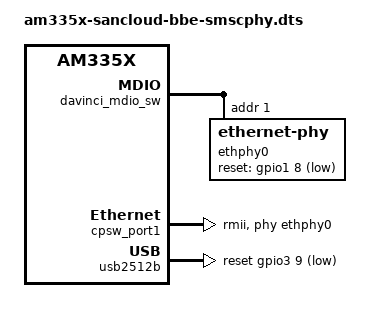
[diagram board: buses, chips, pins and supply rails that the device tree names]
// SPDX-License-Identifier: GPL-2.0-only
/*
 * Copyright (C) 2012 Texas Instruments Incorporated - https://www.ti.com/
 */

#include "am335x-sancloud-bbe.dts"

&cpsw_default {
	pinctrl-single,pins = <
		/* Slave 1 */
		AM33XX_PADCONF(AM335X_PIN_MII1_TXD0, PIN_OUTPUT, MUX_MODE1)	/* mii1_txd0.mii1_txd0 */
		AM33XX_PADCONF(AM335X_PIN_MII1_TXD1, PIN_OUTPUT, MUX_MODE1)	/* mii1_txd1.mii1_txd1 */
		AM33XX_PADCONF(AM335X_PIN_MII1_TX_EN, PIN_OUTPUT, MUX_MODE1)	/* mii1_txen.rmii1_txen */
		AM33XX_PADCONF(AM335X_PIN_MII1_CRS, PIN_INPUT, MUX_MODE1)	/* mii1_crs.rmii1_crs_dv */
		AM33XX_PADCONF(AM335X_PIN_MII1_RXD0, PIN_INPUT, MUX_MODE1)	/* mii1_rxd0.rmii1_rxd0 */
		AM33XX_PADCONF(AM335X_PIN_MII1_RXD1, PIN_INPUT, MUX_MODE1)	/* mii1_rxd1.rmii1_rxd1 */
		AM33XX_PADCONF(AM335X_PIN_MII1_RX_ER, PIN_INPUT, MUX_MODE1)	/* mii1_rx_err.mii1_rx_err */
		AM33XX_PADCONF(AM335X_PIN_RMII1_REF_CLK, PIN_INPUT, MUX_MODE0)	/* mii1_refclk.mii1_refclk */
	>;
};

&cpsw_sleep {
	pinctrl-single,pins = <
		/* Slave 1 reset value */
		AM33XX_PADCONF(AM335X_PIN_MII1_TXD0, PIN_INPUT_PULLDOWN, MUX_MODE7)
		AM33XX_PADCONF(AM335X_PIN_MII1_TXD1, PIN_INPUT_PULLDOWN, MUX_MODE7)
		AM33XX_PADCONF(AM335X_PIN_MII1_TX_EN, PIN_INPUT_PULLDOWN, MUX_MODE7)
		AM33XX_PADCONF(AM335X_PIN_MII1_CRS, PIN_INPUT_PULLDOWN, MUX_MODE7)
		AM33XX_PADCONF(AM335X_PIN_MII1_RXD0, PIN_INPUT_PULLDOWN, MUX_MODE7)
		AM33XX_PADCONF(AM335X_PIN_MII1_RXD1, PIN_INPUT_PULLDOWN, MUX_MODE7)
		AM33XX_PADCONF(AM335X_PIN_MII1_RX_ER, PIN_INPUT_PULLDOWN, MUX_MODE7)
		AM33XX_PADCONF(AM335X_PIN_RMII1_REF_CLK, PIN_INPUT_PULLDOWN, MUX_MODE7)
	>;
};

&usb_hub_ctrl {
	pinctrl-single,pins = <
		AM33XX_PADCONF(AM335X_PIN_MII1_TX_CLK, PIN_OUTPUT_PULLUP, MUX_MODE7)	/* mii1_txclk.gpio3_9 */
	>;
};

/delete-node/ &ethphy0;

&davinci_mdio_sw {
	ethphy0: ethernet-phy@1 {
		reg = <1>;
		reset-gpios = <&gpio1 8 GPIO_ACTIVE_LOW>;
		reset-assert-us = <100>;
		reset-deassert-us = <10>;
	};
};

&cpsw_port1 {
	phy-handle = <&ethphy0>;
	phy-mode = "rmii";
};

&usb2512b {
	reset-gpios = <&gpio3 9 GPIO_ACTIVE_LOW>;
};
